# otbn: IP-XACT component
VLNV tenstorrent.com:ocah:otbn:1.0

## Address spaces and blocks
otbn_mmap.otbn: base 'h0, range 'hc000, width 32

## Registers
Registers are 32-bit, read-write, reset 0x0 unless marked. A register's access mark holds for its fields unless they carry their own. Offsets are from the block's base; lines under a group give offsets from that group; [hi:lo] are bit positions; {n}, {i} and the like mark numbered series; 'fields as' and 'values as' point back to an identical list; <NAME> marks a mode.

## otbn_mmap.otbn — Programmable coprocessor for asymmetric cryptography with SCA and FI countermeasures
Base 0x00000000
0x00 INTR_STATE
  [0] done write-1-clears — OTBN has completed the operation.
0x04 INTR_ENABLE
  [0] done — Enable interrupt when !!INTR_STATE.done is set.
0x08 INTR_TEST wo
  [0] done — Write 1 to force !!INTR_STATE.done to 1.
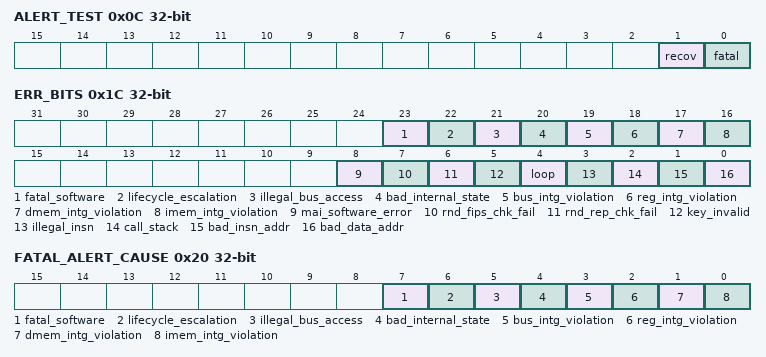
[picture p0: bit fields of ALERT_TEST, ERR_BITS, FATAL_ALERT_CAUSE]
0x0C ALERT_TEST wo
  [1] recov — Write 1 to trigger one alert event of this kind.
  [0] fatal — Write 1 to trigger one alert event of this kind.
0x10 CMD wo
  [7:0] cmd — The operation to perform. | Value | Name | Description | |:------|:--------------|:------------| | 0xd8 | EXECUTE | Starts the execution of the program stored in the instruction memory, starting at address zero. | | 0xc3 | SEC_WIPE_DMEM | Securely removes all contents from the data memory. | | 0x1e | SEC_WIPE_IMEM | Securely removes all contents from the instruction memory. |
0x14 CTRL
  [0] software_errs_fatal — Controls the reaction to software errors. When set software errors produce fatal errors, rather than recoverable errors. Writes are ignored if OTBN is not idle.
0x18 STATUS ro reset 0x4
  [7:0] status — Indicates the current operational state OTBN is in. All BUSY values represent an operation started by a write to the !!CMD register. | Value | Name | Description | |:------|:-------------------|:------------------------------------------------------| | 0x00 | IDLE | OTBN is idle: it is not performing any action. | | 0x01 | BUSY_EXECUTE | OTBN is busy executing software. | | 0x02 | BUSY_SEC_WIPE_DMEM | OTBN is busy securely wiping the data memory. | | 0x03 | BUSY_SEC_WIPE_IMEM | OTBN is busy securely wiping the instruction memory. | | 0x04 | BUSY_SEC_WIPE_INT | OTBN is busy securely wiping the internal state. | | 0xFF | LOCKED | OTBN is locked as reaction to a fatal error, and must be reset to unlock it again. See also the section "Reaction to Fatal Errors". |
0x1C ERR_BITS
  [23] fatal_software — A `FATAL_SOFTWARE` error was observed.
  [22] lifecycle_escalation — A `LIFECYCLE_ESCALATION` error was observed.
  [21] illegal_bus_access — An `ILLEGAL_BUS_ACCESS` error was observed.
  [20] bad_internal_state — A `BAD_INTERNAL_STATE` error was observed.
  [19] bus_intg_violation — A `BUS_INTG_VIOLATION` error was observed.
  [18] reg_intg_violation — A `REG_INTG_VIOLATION` error was observed.
  [17] dmem_intg_violation — A `DMEM_INTG_VIOLATION` error was observed.
  [16] imem_intg_violation — A `IMEM_INTG_VIOLATION` error was observed.
  [8] mai_software_error — An `MAI_SOFTWARE_ERROR` error was observed.
  [7] rnd_fips_chk_fail — An `RND_FIPS_CHK_FAIL` error was observed.
  [6] rnd_rep_chk_fail — An `RND_REP_CHK_FAIL` error was observed.
  [5] key_invalid — A `KEY_INVALID` error was observed.
  [4] loop — A `LOOP` error was observed.
  [3] illegal_insn — An `ILLEGAL_INSN` error was observed.
  [2] call_stack — A `CALL_STACK` error was observed.
  [1] bad_insn_addr — A `BAD_INSN_ADDR` error was observed.
  [0] bad_data_addr — A `BAD_DATA_ADDR` error was observed.
0x20 FATAL_ALERT_CAUSE ro
  [7] fatal_software — A `FATAL_SOFTWARE` error was observed.
  [6] lifecycle_escalation — A `LIFECYCLE_ESCALATION` error was observed.
  [5] illegal_bus_access — A `ILLEGAL_BUS_ACCESS` error was observed.
  [4] bad_internal_state — A `BAD_INTERNAL_STATE` error was observed.
  [3] bus_intg_violation — A `BUS_INTG_VIOLATION` error was observed.
  [2] reg_intg_violation — A `REG_INTG_VIOLATION` error was observed.
  [1] dmem_intg_violation — A `DMEM_INTG_VIOLATION` error was observed.
  [0] imem_intg_violation — A `IMEM_INTG_VIOLATION` error was observed.
0x24 INSN_CNT
  [31:0] insn_cnt — The number of executed instructions.
0x28 LOAD_CHECKSUM
  [31:0] checksum — Checksum accumulator

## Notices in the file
SPDX-License-Identifier: Apache-2.0
SPDX-FileCopyrightText: 2026 Tenstorrent USA, Inc.
